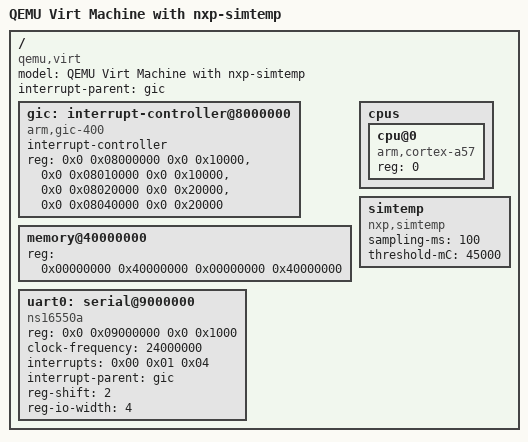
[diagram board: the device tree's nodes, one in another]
/dts-v1/;

/ {
    model = "QEMU Virt Machine with nxp-simtemp";
    compatible = "qemu,virt", "nxp,simtemp-board";

    #address-cells = <2>;
    #size-cells = <2>;

    interrupt-parent = <&gic>;

    gic: interrupt-controller@8000000 {
        compatible = "arm,gic-400";
        #interrupt-cells = <3>;
        interrupt-controller;
        reg = <0x0 0x08000000 0x0 0x10000>,
              <0x0 0x08010000 0x0 0x10000>,
              <0x0 0x08020000 0x0 0x20000>,
              <0x0 0x08040000 0x0 0x20000>;
    };

    memory@40000000 {
        device_type = "memory";
        reg = <0x00000000 0x40000000 0x00000000 0x40000000>;
    };

    cpus {
        #address-cells = <1>;
        #size-cells = <0>;
        cpu@0 {
            device_type = "cpu";
            compatible = "arm,cortex-a57";
            reg = <0>;
        };
    };

    uart0: serial@9000000 {
        compatible = "ns16550a";
        reg = <0x0 0x09000000 0x0 0x1000>;
        clock-frequency = <24000000>;
        interrupts = <0x00 0x01 0x04>;
        interrupt-parent = <&gic>;
        reg-shift = <2>;
        reg-io-width = <4>;
    };

    simtemp {
        compatible = "nxp,simtemp";
        sampling-ms = <100>;
        threshold-mC = <45000>;
        status = "okay";
    };
};
